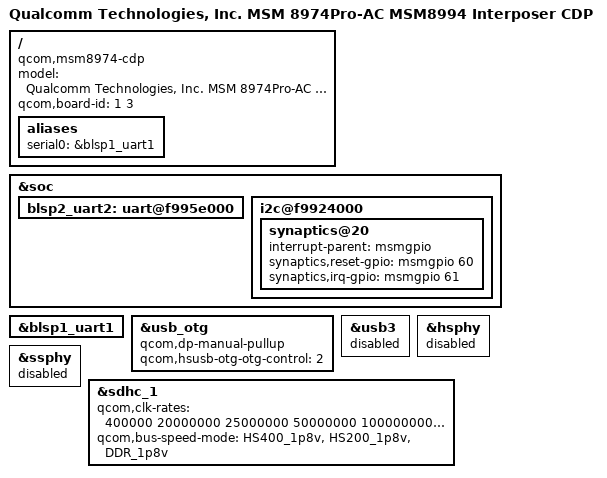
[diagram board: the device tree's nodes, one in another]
/* Copyright (c) 2013-2014, The Linux Foundation. All rights reserved.
 *
 * This program is free software; you can redistribute it and/or modify
 * it under the terms of the GNU General Public License version 2 and
 * only version 2 as published by the Free Software Foundation.
 *
 * This program is distributed in the hope that it will be useful,
 * but WITHOUT ANY WARRANTY; without even the implied warranty of
 * MERCHANTABILITY or FITNESS FOR A PARTICULAR PURPOSE.  See the
 * GNU General Public License for more details.
 */


/dts-v1/;

#include "msm8974pro-pm8994.dtsi"
&soc {
	/*
	 * This workaround is needed as 8974 config fails to build
	 * due to the missing blsp2_uart2 label refernce with interposer.
	 * The dummy node needs to be defined before the msm8994-mtp.dtsi
	 * is included as that file has a reference to the blsp2_uart2 label
	 */
	blsp2_uart2: uart@f995e000 {
	};
};
#include "msm8994-cdp.dtsi"

/ {
	model = "Qualcomm Technologies, Inc. MSM 8974Pro-AC MSM8994 Interposer CDP";
	compatible = "qcom,msm8974-cdp", "qcom,msm8974", "qcom,cdp";
	qcom,board-id = <1 3>;

	aliases {
		serial0 = &blsp1_uart1;
	};
};

&blsp1_uart1 {
	status = "ok";
};

&usb_otg {
	qcom,dp-manual-pullup;
	qcom,hsusb-otg-otg-control = <2>;
	status = "ok";
};

&usb3 {
	status = "disabled";
};

&hsphy {
	status = "disabled";
};

&ssphy {
	status = "disabled";
};

&sdhc_1 {
	qcom,clk-rates = <400000 20000000 25000000 50000000 100000000 192000000 384000000>;
	qcom,bus-speed-mode = "HS400_1p8v", "HS200_1p8v", "DDR_1p8v";
};

&soc {
	i2c@f9924000 {
		synaptics@20 {
			interrupt-parent = <&msmgpio>;
			synaptics,reset-gpio = <&msmgpio 60 0x00>;
			synaptics,irq-gpio = <&msmgpio 61 0x2008>;
		};
	};
};
